# R7FA0E209 register map
Vendor: Renesas Electronics Corporation; Series: RA0; File version: 1.00.00
CPU: CM23 r1p0, little endian, no MPU, no FPU, VTOR, 2 interrupt priority bits, 64 interrupts
Registers are 16-bit, read-write, reset 0x0 unless marked. A register's access mark holds for its fields unless they carry their own. Offsets are from the block's base; [hi:lo] are bit positions; {n}, {i} and the like mark numbered series.

## PORT5 — Port 5 Control
Base 0x400A00A0
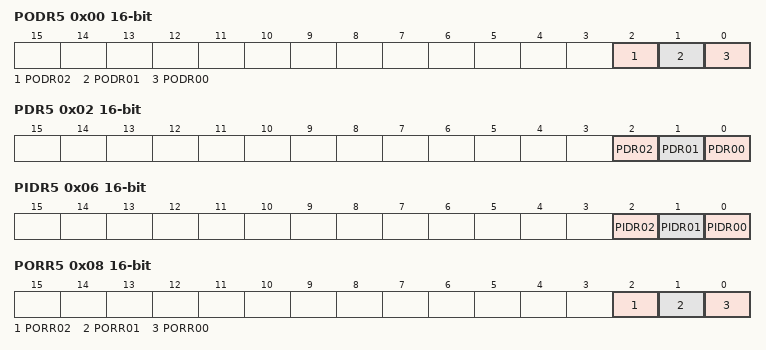
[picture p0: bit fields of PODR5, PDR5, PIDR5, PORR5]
0x00 PODR5 — Port 5 Output Data Register
  [all] fields
    0=Low output; 1=High output
  [2] PODR02 — P502 Output Data
  [1] PODR01 — P501 Output Data
  [0] PODR00 — P500 Output Data
0x02 PDR5 — Port 5 Direction Register
  [all] fields
    0=Output 0; 1=Output 1
  [2] PDR02 — P502 Direction
  [1] PDR01 — P501 Direction
  [0] PDR00 — P500 Direction
0x06 PIDR5 ro (reset mask 0xFFF8) — Port 5 State Register
  [all] fields
    0=Low level; 1=High level
  [2] PIDR02 — P502 State
  [1] PIDR01 — P501 State
  [0] PIDR00 — P500 State
0x08 PORR5 wo — Port 5 Output Reset Register
  [all] fields
    0=No effect on output; 1=Low output
  [2] PORR02 — P502 Output Reset
  [1] PORR01 — P501 Output Reset
  [0] PORR00 — P500 Output Reset
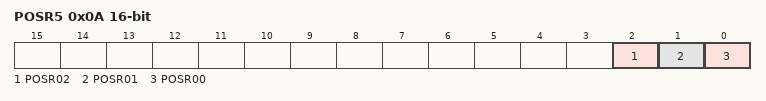
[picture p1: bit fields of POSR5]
0x0A POSR5 wo — Port 5 Output Set Register
  [all] fields
    0=No effect on output; 1=High output
  [2] POSR02 — P502 Output Set
  [1] POSR01 — P501 Output Set
  [0] POSR00 — P500 Output Set

## PORT9 — Port 9 Control
Base 0x400A0120
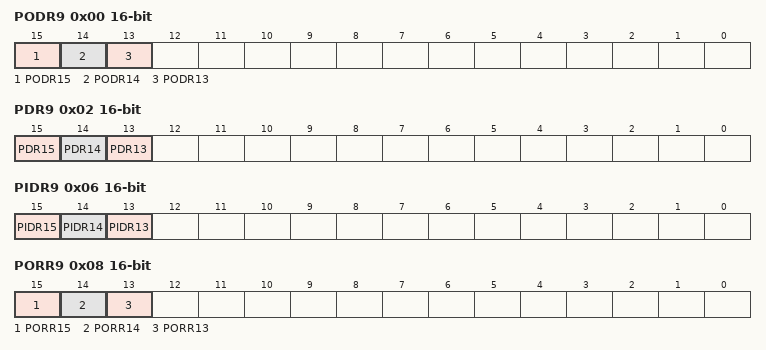
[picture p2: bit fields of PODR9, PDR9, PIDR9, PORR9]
0x00 PODR9 — Port 9 Output Data Register
  [all] fields
    0=Low output; 1=High output
  [15] PODR15 — P915 Output Data
  [14] PODR14 — P914 Output Data
  [13] PODR13 — P913 Output Data
0x02 PDR9 — Port 9 Direction Register
  [all] fields
    0=Output 0; 1=Output 1
  [15] PDR15 — P915 Direction
  [14] PDR14 — P914 Direction
  [13] PDR13 — P913 Direction
0x06 PIDR9 ro (reset mask 0x1FFF) — Port 9 State Register
  [all] fields
    0=Low level; 1=High level
  [15] PIDR15 — P915 State
  [14] PIDR14 — P914 State
  [13] PIDR13 — P913 State
0x08 PORR9 wo — Port 9 Output Reset Register
  [all] fields
    0=No effect on output; 1=Low output
  [15] PORR15 — P915 Output Reset
  [14] PORR14 — P914 Output Reset
  [13] PORR13 — P913 Output Reset
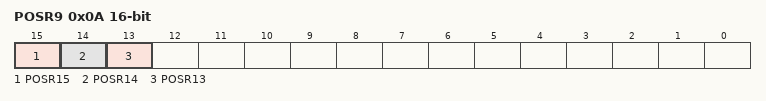
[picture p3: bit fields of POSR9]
0x0A POSR9 wo — Port 9 Output Set Register
  [all] fields
    0=No effect on output; 1=High output
  [15] POSR15 — P915 Output Set
  [14] POSR14 — P914 Output Set
  [13] POSR13 — P913 Output Set

## PORGA — Product Organize
Base 0x400A1000
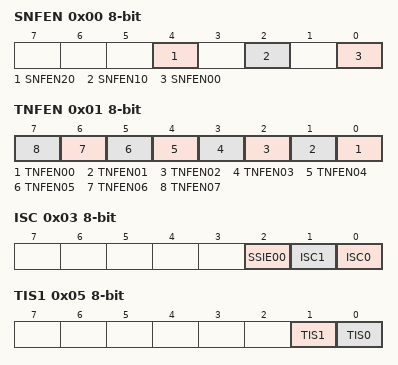
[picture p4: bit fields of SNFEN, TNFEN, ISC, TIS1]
0x00 SNFEN 8-bit — SAU Noise Filter Enable Register
  [all] fields
    0=Noise filter OFF; 1=Noise filter ON
  [4] SNFEN20 — Use of Noise Filter of RXD2 Pin
  [2] SNFEN10 — Use of Noise Filter of RXD1 Pin
  [0] SNFEN00 — Use of Noise Filter of RXD0 Pin
0x01 TNFEN 8-bit — TAU Noise Filter Enable Register
  [all] fields
    0=Turns the noise filter off; 1=Turns the noise filter on
  [n] TNFEN{n:02} (n=0..7) — Enabling or Disabling Use of the Noise Filter for the TI{n:02} Pin
0x03 ISC 8-bit — Input Switch Control Register
  [2] SSIE00 — Setting of the SSI00 Input of Channel 0 in the Communications Through SPI00 in the Slave Mode
    0=The SSI00 input is disabled; 1=The SSI00 input is enabled
  [1] ISC1 — Switching Channel 7 Input of Timer Array Unit
    0=Uses the input signal of the TI07 pin as a timer input (normal operation); 1=Input signal of the RXD2 pin is used as timer input (detects the wakeup signal and measures the low width of the break field and the pulse width of the sync field)
  [0] ISC0 — Switching External Interrupt (IRQ0) Input
    0=Uses the input signal of the IRQ0 pin as an external interrupt (normal operation); 1=Uses the input signal of the RXD2 pin as an external interrupt (wakeup signal detection)
0x04 TIS0 8-bit — Timer Input Select Register 0
  [2:0] TIS — Selection of Timer Input Used with Channel 5
    0=Input signal of timer input pin (TI05); 3=Middle-speed on-chip oscillator (MOCO); 4=Low-speed on-chip oscillator (LOCO); 5=Sub System clock (FSUB); other=Others (Setting prohibited)
0x05 TIS1 8-bit — Timer Input Select Register 1
  [1] TIS1 — Selection of Timer Input Used with Channel 1
    0=Input signal of timer input pin (TI01); 1=Event input signal from ELC
  [0] TIS0 — Selection of Timer Input Used with Channel 0
    0=Input signal of timer input pin (TI00); 1=Event input signal from ELC
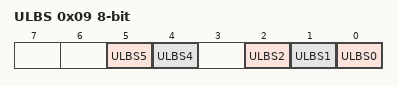
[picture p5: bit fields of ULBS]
0x09 ULBS 8-bit — UART Loopback Select Register
  [5] ULBS5 — Selection of the UARTA1 Loopback Function
    0=Inputs the states of the RXDA1 pin of serial array unit UARTA1 to the reception shift register; 1=Loops back output from the transmission shift register to the reception shift register
  [4] ULBS4 — Selection of the UARTA0 Loopback Function
    0=Inputs the states of the RXDA0 pin of serial array unit UARTA0 to the reception shift register; 1=Loops back output from the transmission shift register to the reception shift register
  [2] ULBS2 — Selection of the UART2 Loopback Function
    0=Inputs the states of the RXD2 pin of serial array unit UART2 to the reception shift register; 1=Loops back output from the transmission shift register to the reception shift register
  [1] ULBS1 — Selection of the UART1 Loopback Function
    0=Inputs the states of the RXD1 pin of serial array unit UART1 to the reception shift register; 1=Loops back output from the transmission shift register to the reception shift register
  [0] ULBS0 — Selection of the UART0 Loopback Function
    0=Inputs the states of the RXD0 pin of serial array unit UART0 to the reception shift register; 1=Loops back output from the transmission shift register to the reception shift register

## PCLBUZ — Clock Output/Buzzer Output Controller
Base 0x400A3B00
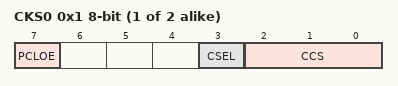
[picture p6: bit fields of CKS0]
{0x1+i} CKS{i} (i=0..1) 8-bit — Clock Out Control Register {i}
  [7] PCLOE — Clock Out Enable
    0=Disable clock out; 1=Enable clock out
  [3] CSEL — Clock Out Select
    0=FMAIN; 1=FSUB
  [2:0] CCS — Clock Out Divide Select
    0=value after reset FMAIN (When CKS%s.CSEL = 0) FSUB (When CKS%s.CSEL = 1); 1=FMAIN × 1/2 (When CKS%s.CSEL = 0) FSUB × 1/2 (When CKS%s.CSEL = 1); 2=FMAIN × 1/2^2 (When CKS%s.CSEL = 0) FSUB × 1/2^2 (When CKS%s.CSEL = 1); 3=FMAIN × 1/2^3 (When CKS%s.CSEL = 0) FSUB × 1/2^3 (When CKS%s.CSEL = 1); 4=FMAIN × 1/2^4 (When CKS%s.CSEL = 0) FSUB × 1/2^4 (When CKS%s.CSEL = 1); 5=FMAIN × 1/2^11 (When CKS%s.CSEL = 0) FSUB × 1/2^5 (When CKS%s.CSEL = 1); 6=FMAIN 1/2^12 (When CKS%s.CSEL = 0) FSUB × 1/2^6 (When CKS%s.CSEL = 1); 7=FMAIN × 1/2^13 (When CKS%s.CSEL = 0) FSUB × 1/2^7 (When CKS%s.CSEL = 1)

## TRNG — True Random Number Generator
Base 0x400D1000
0x00 TRNGSDR 8-bit ro — TRNG Seed Data Register
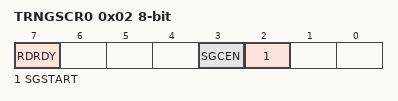
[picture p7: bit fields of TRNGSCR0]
0x02 TRNGSCR0 8-bit — TRNG Seed Command Register 0
  [7] RDRDY ro — Read Ready
  [3] SGCEN — Seed Generation Circuit Enable
    0=Seed generation circuit is disabled; 1=Seed generation circuit is enabled
  [2] SGSTART wo — Seed Generation Start
    0=No effect; 1=Start to generate the seed data
0x03 TRNGSCR1 8-bit — TRNG Seed Command Register 1
  [0] INTEN — TRNG Interrupt Enable
    0=TRNG interrupt is disabled; 1=TRNG interrupt is enabled
